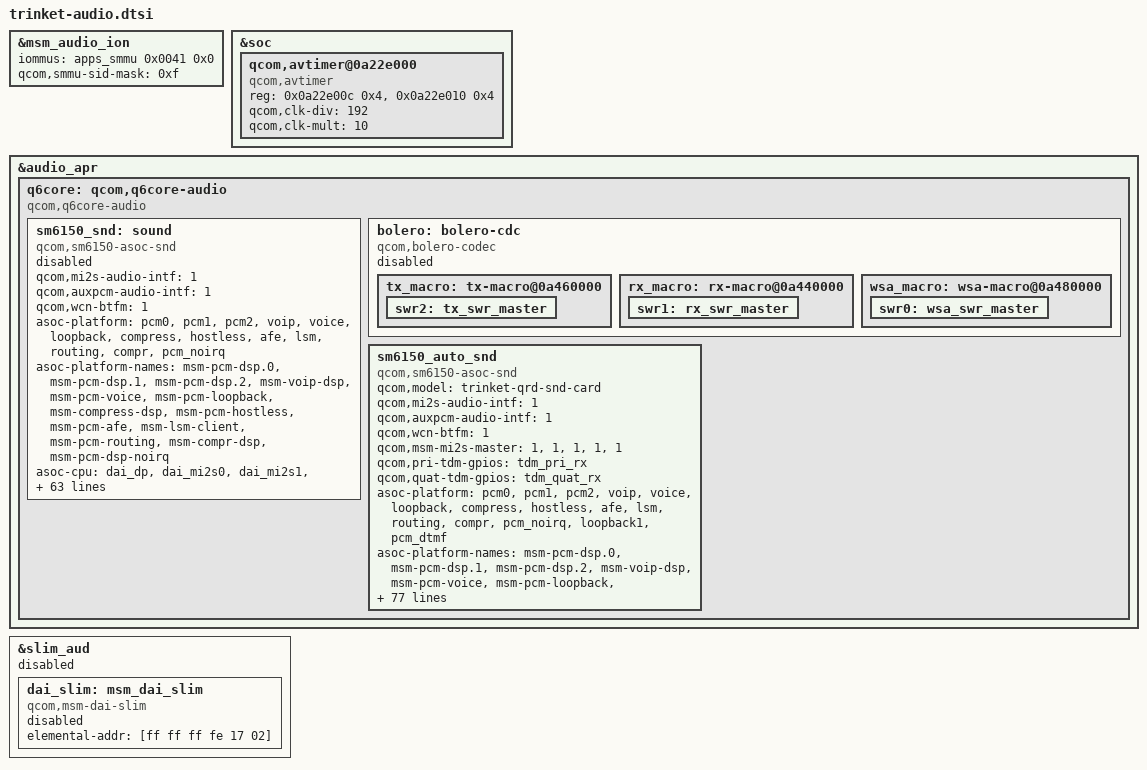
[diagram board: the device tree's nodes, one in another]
/*
 * Copyright (c) 2019-2020, The Linux Foundation. All rights reserved.
 *
 * This program is free software; you can redistribute it and/or modify
 * it under the terms of the GNU General Public License version 2 and
 * only version 2 as published by the Free Software Foundation.
 *
 * This program is distributed in the hope that it will be useful,
 * but WITHOUT ANY WARRANTY; without even the implied warranty of
 * MERCHANTABILITY or FITNESS FOR A PARTICULAR PURPOSE.  See the
 * GNU General Public License for more details.
 */

#include "msm-audio-lpass.dtsi"

&msm_audio_ion {
	iommus = <&apps_smmu 0x0041 0x0>;
	qcom,smmu-sid-mask = /bits/ 64 <0xf>;
};

&soc {
	qcom,avtimer@0a22e000 {
		compatible = "qcom,avtimer";
		reg = <0x0a22e00c 0x4>,
		      <0x0a22e010 0x4>;
		reg-names = "avtimer_lsb_addr", "avtimer_msb_addr";
		qcom,clk-div = <192>;
		qcom,clk-mult = <10>;
	};
};

&audio_apr {
	q6core: qcom,q6core-audio {
		compatible = "qcom,q6core-audio";
		status = "ok";
		sm6150_snd: sound {
			status = "disabled";
		};

		bolero: bolero-cdc {
                        status = "disabled";
			compatible = "qcom,bolero-codec";
			tx_macro: tx-macro@0a460000 {
				swr2: tx_swr_master {
				};
			};

			rx_macro: rx-macro@0a440000 {
				swr1: rx_swr_master {
				};
			};

			wsa_macro: wsa-macro@0a480000 {
				swr0: wsa_swr_master {
				};
			};
		};
	};
};

&q6core {
	sm6150_auto_snd{
		compatible = "qcom,sm6150-asoc-snd";
                qcom,model = "trinket-qrd-snd-card";
		qcom,mi2s-audio-intf = <1>;
		qcom,auxpcm-audio-intf = <1>;
		qcom,wcn-btfm = <1>;
		qcom,msm-mi2s-master = <1>, <1>, <1>, <1>, <1>;

		qcom,pri-tdm-gpios = <&tdm_pri_rx>;
		qcom,quat-tdm-gpios = <&tdm_quat_rx>;

		asoc-platform = <&pcm0>, <&pcm1>, <&pcm2>, <&voip>, <&voice>,
				<&loopback>, <&compress>, <&hostless>,
				<&afe>, <&lsm>, <&routing>, <&compr>,
				<&pcm_noirq>, <&loopback1>, <&pcm_dtmf>;
		asoc-platform-names = "msm-pcm-dsp.0", "msm-pcm-dsp.1",
				"msm-pcm-dsp.2", "msm-voip-dsp",
				"msm-pcm-voice", "msm-pcm-loopback",
				"msm-compress-dsp", "msm-pcm-hostless",
				"msm-pcm-afe", "msm-lsm-client",
				"msm-pcm-routing", "msm-compr-dsp",
				"msm-pcm-dsp-noirq", "msm-pcm-loopback.1",
				"msm-pcm-dtmf";
		asoc-cpu = <&dai_hdmi>, <&dai_dp>,
				<&dai_mi2s0>, <&dai_mi2s1>,
				<&dai_mi2s2>, <&dai_mi2s3>,
				<&dai_mi2s4>, <&dai_pri_auxpcm>,
				<&dai_sec_auxpcm>, <&dai_tert_auxpcm>,
				<&dai_quat_auxpcm>, <&dai_quin_auxpcm>,
				<&afe_pcm_rx>, <&afe_pcm_tx>,
				<&afe_proxy_rx>, <&afe_proxy_tx>,
				<&afe_pcm_rx_1>, <&afe_proxy_tx_1>,
				<&incall_record_rx>, <&incall_record_tx>,
				<&incall_music_rx>, <&incall_music_2_rx>,
				<&usb_audio_rx>, <&usb_audio_tx>,
				<&dai_pri_tdm_rx_0>, <&dai_pri_tdm_rx_1>,
				<&dai_pri_tdm_rx_2>, <&dai_pri_tdm_rx_3>,
				<&dai_pri_tdm_tx_0>, <&dai_pri_tdm_tx_1>,
				<&dai_pri_tdm_tx_2>, <&dai_pri_tdm_tx_3>,
				<&dai_sec_tdm_rx_0>, <&dai_sec_tdm_rx_1>,
				<&dai_sec_tdm_rx_2>, <&dai_sec_tdm_rx_3>,
				<&dai_sec_tdm_rx_7>, <&dai_sec_tdm_tx_0>,
				<&dai_sec_tdm_tx_1>, <&dai_sec_tdm_tx_2>,
				<&dai_sec_tdm_tx_3>, <&dai_tert_tdm_rx_0>,
				<&dai_tert_tdm_rx_1>, <&dai_tert_tdm_rx_2>,
				<&dai_tert_tdm_rx_3>, <&dai_tert_tdm_rx_4>,
				<&dai_tert_tdm_tx_0>, <&dai_tert_tdm_tx_1>,
				<&dai_tert_tdm_tx_2>, <&dai_tert_tdm_tx_3>,
				<&dai_tert_tdm_tx_7>, <&dai_quat_tdm_rx_0>,
				<&dai_quat_tdm_rx_1>, <&dai_quat_tdm_rx_2>,
				<&dai_quat_tdm_rx_3>, <&dai_quat_tdm_rx_7>,
				<&dai_quat_tdm_tx_0>, <&dai_quat_tdm_tx_1>,
				<&dai_quat_tdm_tx_2>, <&dai_quat_tdm_tx_3>,
				<&dai_quat_tdm_tx_7>, <&dai_quin_tdm_rx_0>,
				<&dai_quin_tdm_rx_1>, <&dai_quin_tdm_rx_2>,
				<&dai_quin_tdm_rx_3>, <&dai_quin_tdm_rx_7>,
				<&dai_quin_tdm_tx_0>, <&dai_quin_tdm_tx_1>,
				<&dai_quin_tdm_tx_2>, <&dai_quin_tdm_tx_3>,
				<&dai_quin_tdm_tx_7>;
		asoc-cpu-names = "msm-dai-q6-hdmi.8",  "msm-dai-q6-dp.24608",
				"msm-dai-q6-mi2s.0", "msm-dai-q6-mi2s.1",
				"msm-dai-q6-mi2s.2", "msm-dai-q6-mi2s.3",
				"msm-dai-q6-mi2s.4", "msm-dai-q6-auxpcm.1",
				"msm-dai-q6-auxpcm.2", "msm-dai-q6-auxpcm.3",
				"msm-dai-q6-auxpcm.4", "msm-dai-q6-auxpcm.5",
				"msm-dai-q6-dev.224", "msm-dai-q6-dev.225",
				"msm-dai-q6-dev.241", "msm-dai-q6-dev.240",
				"msm-dai-q6-dev.226", "msm-dai-q6-dev.242",
				"msm-dai-q6-dev.32771", "msm-dai-q6-dev.32772",
				"msm-dai-q6-dev.32773", "msm-dai-q6-dev.32770",
				"msm-dai-q6-dev.28672", "msm-dai-q6-dev.28673",
				"msm-dai-q6-tdm.36864", "msm-dai-q6-tdm.36866",
				"msm-dai-q6-tdm.36868", "msm-dai-q6-tdm.36870",
				"msm-dai-q6-tdm.36865", "msm-dai-q6-tdm.36867",
				"msm-dai-q6-tdm.36869", "msm-dai-q6-tdm.36871",
				"msm-dai-q6-tdm.36880", "msm-dai-q6-tdm.36882",
				"msm-dai-q6-tdm.36884", "msm-dai-q6-tdm.36886",
				"msm-dai-q6-tdm.36894", "msm-dai-q6-tdm.36881",
				"msm-dai-q6-tdm.36883", "msm-dai-q6-tdm.36885",
				"msm-dai-q6-tdm.36887", "msm-dai-q6-tdm.36896",
				"msm-dai-q6-tdm.36898", "msm-dai-q6-tdm.36900",
				"msm-dai-q6-tdm.36902", "msm-dai-q6-tdm.36904",
				"msm-dai-q6-tdm.36897", "msm-dai-q6-tdm.36899",
				"msm-dai-q6-tdm.36901", "msm-dai-q6-tdm.36903",
				"msm-dai-q6-tdm.36911", "msm-dai-q6-tdm.36912",
				"msm-dai-q6-tdm.36914", "msm-dai-q6-tdm.36916",
				"msm-dai-q6-tdm.36918", "msm-dai-q6-tdm.36926",
				"msm-dai-q6-tdm.36913", "msm-dai-q6-tdm.36915",
				"msm-dai-q6-tdm.36917", "msm-dai-q6-tdm.36919",
				"msm-dai-q6-tdm.36927", "msm-dai-q6-tdm.36928",
				"msm-dai-q6-tdm.36930", "msm-dai-q6-tdm.36932",
				"msm-dai-q6-tdm.36934", "msm-dai-q6-tdm.36942",
				"msm-dai-q6-tdm.36929", "msm-dai-q6-tdm.36931",
				"msm-dai-q6-tdm.36933", "msm-dai-q6-tdm.36935",
				"msm-dai-q6-tdm.36943";
		asoc-codec = <&stub_codec>;
		asoc-codec-names = "msm-stub-codec.1";
		qcom,msm_audio_ssr_devs = <&audio_apr>, <&q6core>;
	};




	sm6150_snd: sound {
		compatible = "qcom,sm6150-asoc-snd";
		qcom,mi2s-audio-intf = <1>;
		qcom,auxpcm-audio-intf = <1>;
		qcom,wcn-btfm = <1>;
		status = "disabled";

		asoc-platform = <&pcm0>, <&pcm1>, <&pcm2>, <&voip>, <&voice>,
				<&loopback>, <&compress>, <&hostless>,
				<&afe>, <&lsm>, <&routing>, <&compr>,
				<&pcm_noirq>;
		asoc-platform-names = "msm-pcm-dsp.0", "msm-pcm-dsp.1",
				"msm-pcm-dsp.2", "msm-voip-dsp",
				"msm-pcm-voice", "msm-pcm-loopback",
				"msm-compress-dsp", "msm-pcm-hostless",
				"msm-pcm-afe", "msm-lsm-client",
				"msm-pcm-routing", "msm-compr-dsp",
				"msm-pcm-dsp-noirq";
		asoc-cpu = <&dai_dp>,
				<&dai_mi2s0>, <&dai_mi2s1>,
				<&dai_mi2s2>, <&dai_mi2s3>,
				<&dai_mi2s4>, <&dai_pri_auxpcm>,
				<&dai_sec_auxpcm>, <&dai_tert_auxpcm>,
				<&dai_quat_auxpcm>, <&dai_quin_auxpcm>,
				<&afe_pcm_rx>, <&afe_pcm_tx>, <&afe_proxy_rx>,
				<&afe_proxy_tx>, <&incall_record_rx>,
				<&incall_record_tx>, <&incall_music_rx>,
				<&incall_music_2_rx>,
				<&sb_7_rx>, <&sb_7_tx>, <&sb_8_tx>, <&sb_8_rx>,
				<&proxy_rx>, <&proxy_tx>,
				<&usb_audio_rx>, <&usb_audio_tx>,
				<&dai_pri_tdm_rx_0>, <&dai_pri_tdm_tx_0>,
				<&dai_sec_tdm_rx_0>, <&dai_sec_tdm_tx_0>,
				<&dai_tert_tdm_rx_0>, <&dai_tert_tdm_tx_0>,
				<&dai_quat_tdm_rx_0>, <&dai_quat_tdm_tx_0>,
				<&dai_quin_tdm_rx_0>, <&dai_quin_tdm_tx_0>,
				<&wsa_cdc_dma_0_rx>, <&wsa_cdc_dma_0_tx>,
				<&wsa_cdc_dma_1_rx>, <&wsa_cdc_dma_1_tx>,
				<&wsa_cdc_dma_2_tx>,
				<&rx_cdc_dma_0_rx>, <&tx_cdc_dma_0_tx>,
				<&rx_cdc_dma_1_rx>, <&tx_cdc_dma_1_tx>,
				<&rx_cdc_dma_2_rx>, <&tx_cdc_dma_2_tx>,
				<&rx_cdc_dma_3_rx>, <&tx_cdc_dma_3_tx>,
				<&rx_cdc_dma_4_rx>, <&tx_cdc_dma_4_tx>,
				<&rx_cdc_dma_5_rx>, <&tx_cdc_dma_5_tx>,
				<&rx_cdc_dma_6_rx>, <&rx_cdc_dma_7_rx>;
		asoc-cpu-names = "msm-dai-q6-dp.24608",
				"msm-dai-q6-mi2s.0", "msm-dai-q6-mi2s.1",
				"msm-dai-q6-mi2s.2", "msm-dai-q6-mi2s.3",
				"msm-dai-q6-mi2s.4", "msm-dai-q6-auxpcm.1",
				"msm-dai-q6-auxpcm.2", "msm-dai-q6-auxpcm.3",
				"msm-dai-q6-auxpcm.4", "msm-dai-q6-auxpcm.5",
				"msm-dai-q6-dev.224",
				"msm-dai-q6-dev.225", "msm-dai-q6-dev.241",
				"msm-dai-q6-dev.240", "msm-dai-q6-dev.32771",
				"msm-dai-q6-dev.32772", "msm-dai-q6-dev.32773",
				"msm-dai-q6-dev.32770", "msm-dai-q6-dev.16398",
				"msm-dai-q6-dev.16399", "msm-dai-q6-dev.16401",
				"msm-dai-q6-dev.16400",
				"msm-dai-q6-dev.8194", "msm-dai-q6-dev.8195",
				"msm-dai-q6-dev.28672", "msm-dai-q6-dev.28673",
				"msm-dai-q6-tdm.36864", "msm-dai-q6-tdm.36865",
				"msm-dai-q6-tdm.36880", "msm-dai-q6-tdm.36881",
				"msm-dai-q6-tdm.36896", "msm-dai-q6-tdm.36897",
				"msm-dai-q6-tdm.36912", "msm-dai-q6-tdm.36913",
				"msm-dai-q6-tdm.36928", "msm-dai-q6-tdm.36929",
				"msm-dai-cdc-dma-dev.45056",
				"msm-dai-cdc-dma-dev.45057",
				"msm-dai-cdc-dma-dev.45058",
				"msm-dai-cdc-dma-dev.45059",
				"msm-dai-cdc-dma-dev.45061",
				"msm-dai-cdc-dma-dev.45104",
				"msm-dai-cdc-dma-dev.45105",
				"msm-dai-cdc-dma-dev.45106",
				"msm-dai-cdc-dma-dev.45107",
				"msm-dai-cdc-dma-dev.45108",
				"msm-dai-cdc-dma-dev.45109",
				"msm-dai-cdc-dma-dev.45110",
				"msm-dai-cdc-dma-dev.45111",
				"msm-dai-cdc-dma-dev.45112",
				"msm-dai-cdc-dma-dev.45113",
				"msm-dai-cdc-dma-dev.45114",
				"msm-dai-cdc-dma-dev.45115",
				"msm-dai-cdc-dma-dev.45116",
				"msm-dai-cdc-dma-dev.45118";
		fsa4480-i2c-handle = <&fsa4480>;
	};
};

&slim_aud {
	status = "disabled";
	dai_slim: msm_dai_slim {
		status = "disabled";
		compatible = "qcom,msm-dai-slim";
		elemental-addr = [ff ff ff fe 17 02];
	};
};
